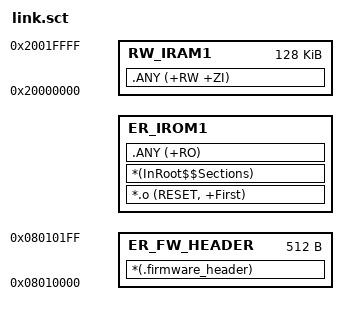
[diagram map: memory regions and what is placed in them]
#!armcc --cpu Cortex-M4 -E
;#!armclang -E --target=arm-arm-none-eabi -mcpu=cortex-m4 -xc

; *************************************************************
; *** Scatter-Loading Description File generated by uVision ***
; *************************************************************

LR_IROM1 0x8010000 0x38000  {    ; load region size_region
  ; firmware_header
  ER_FW_HEADER 0x8010000 0x200 {  
    *(.firmware_header)
  }
  
  ER_IROM1 +0 {  ; load address = up end address add offset
   *.o (RESET, +First)
   *(InRoot$$Sections)
   .ANY (+RO)
  }
  RW_IRAM1 0x20000000 0x00020000  {  ; RW data
   .ANY (+RW +ZI)
  }
}

